# STM32H7RSxx register map
File version: 0.1
CPU: CM7 r0p1, little endian, MPU, FPU, 4 interrupt priority bits
Registers are 32-bit, read-write, reset 0x0 unless marked. A register's access mark holds for its fields unless they carry their own. Offsets are from the block's base; [hi:lo] are bit positions; {n}, {i} and the like mark numbered series.

## FLASH — Embedded Flash memory
Base 0x52002000
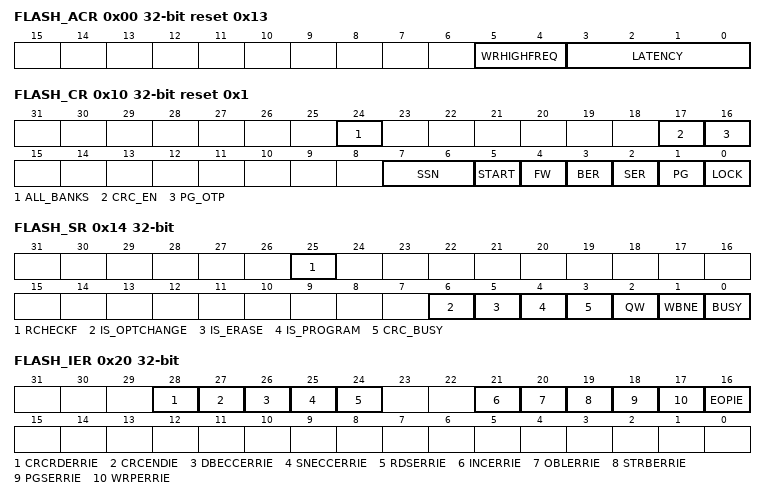
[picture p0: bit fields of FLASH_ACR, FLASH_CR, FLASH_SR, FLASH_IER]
0x00 FLASH_ACR reset 0x13 — Access control register
  [5:4] WRHIGHFREQ — Flash signal delay These bits are used to control the delay between non-volatile memory signals during programming operations. Application software has to program them to the correct value depending on the embedded Flash memory interface frequency. Please refer to Table 27 for details. Note: Embedded Flash does not verify that the configuration is correct.
  [3:0] LATENCY — Read latency These bits are used to control the number of wait states used during read operations on both non-volatile memory banks. The application software has to program them to the correct value depending on the embedded Flash memory interface frequency and voltage conditions. Please refer to Table 27 for details. ... Note: Embedded Flash does not verify that the configuration is correct.
    0=zero wait state used to read a word from non-volatile memory; 1=one wait state used to read a word from non-volatile memory; 2=two wait states used to read a word from non-volatile memory; 7=six wait states used to read a word from non-volatile memory; 15=fifteen wait states used to read from non-volatile memory
0x04 FLASH_KEYR wo — FLASH control key register
  [31:0] CUKEY — Control unlock key Following values must be written to FLASH_KEYR consecutively to unlock FLASH_CR register: 1st key = 0x4567 0123 2nd key = 0xCDEF 89AB Reads to this register returns zero. If above sequence is wrong or performed twice, the FLASH_CR register is locked until the next system reset, and access to it generates a bus error.
0x10 FLASH_CR reset 0x1 — FLASH control register
  [24] ALL_BANKS — All banks select bit When this bit is set the erase is done on all Flash Memory sectors. ALL_BANKS is used only if a bank erase is required (BER=1). In all others operations, this control bit is ignored.
  [17] CRC_EN — CRC enable Setting this bit enables the CRC calculation. CRC_EN does not start CRC calculation but enables CRC configuration through FLASH_CRCCR register. When CRC calculation is performed it can be disabled by clearing CRC_EN bit. Doing so sets CRCDATA to 0x0, clears CRC configuration and resets the content of FLASH_CRCDATAR register.
  [16] PG_OTP — Program Enable for OTP Area Set this bit to enable write operations to OTP area.
  [7:6] SSN — Sector erase selection number These bits are used to select the target sector for an erase operation (they are unused otherwise). ...
    0=Sector 0; 1=Sector 1; 7=Sector 7
  [5] START — Erase start control bit This bit is used to start a sector erase or a bank erase operation. The embedded Flash memory resets START when the corresponding operation has been acknowledged. The user application cannot access any embedded Flash memory register until the operation is acknowledged.
  [4] FW — Force write This bit forces a write operation even if the write buffer is not full. In this case all bits not written are set by hardware. The embedded Flash memory resets FW when the corresponding operation has been acknowledged. Note: Using a force-write operation prevents the application from updating later the missing bits with something else than 1, because it is likely that it will lead to permanent ECC error. Write forcing is effective only if the write buffer is not empty (in particular, FW does not start several write operations when the force-write operations are performed consecutively).
  [3] BER — Bank erase request Setting this bit requests a bank erase operation (user Flash memory only). Write protection error is triggered when a bank erase is required and some sectors are protected. BER has a higher priority than SER: if both are set, the embedded Flash memory executes a bank erase.
    0=Bank erase is not requested; 1=Bank erase is requested. Actual erase is started setting START bit in this register.
  [2] SER — Sector erase request Setting this bit requests a sector erase. Write protection error is triggered when a sector erase is required on at least one protected sector. BER has a higher priority than SER: if both bits are set, the embedded Flash memory executes a bank erase.
    0=Sector erase not requested; 1=Sector erase requested
  [1] PG — Internal buffer control bit Setting this bit enables internal buffer for write operations. This allows preparing program operations even if a sector or bank erase is ongoing. When PG is cleared, the internal buffer is disabled for write operations, and all the data stored in the buffer but not sent to the operation queue are lost.
    0=Internal buffer disabled for write operations; 1=Internal buffer enabled for write operations
  [0] LOCK — Configuration lock bit When this bit is set write to all other bits in this register, and to FLASH_IER register, are ignored. Clearing this bit requires the correct write sequence to FLASH_KEYR register (see this register for details). If a wrong sequence is executed, or if the unlock sequence is performed twice, this bit remains locked until the next system reset. During the write access to set LOCK bit from 0 to 1, it is possible to change the other bits of this register.
    0=FLASH_CR and FLASH_IER registers are unlocked; 1=Writes to FLASH_IER, and to other bits than LOCK in FLASH_CR, are ignored
0x14 FLASH_SR ro — FLASH status register
  [25] RCHECKF — Root code check flag This bit returns the status of the root code check performed following the first access to the Flash. This bit is cleared with RCHECKF bit in FLASH_FCR (optional).
    0=Root code check is fail. Reads to Flash returns zero, writes are ignored.; 1=Root code check is pass
  [6] IS_OPTCHANGE — Is an option change This bit is set together with BUSY when an option change operation is ongoing. It is cleared when BUSY is cleared. This flag can also raise with IS_PROGRAM or IS_ERASE, because a program or erase step is ongoing during option change.
  [5] IS_ERASE — Is an erase This bit is set together with BUSY when an erase operation is ongoing. It is cleared when BUSY is cleared. This flag can also raise with IS_OPTCHANGE, because an erase operation can happen during an option change.
  [4] IS_PROGRAM — Is a program This bit is set together with BUSY when a program operation is ongoing. It is cleared when BUSY is cleared. This flag can also raise with IS_OPTCHANGE, because an program operation can happen during an option change.
  [3] CRC_BUSY — CRC busy flag This bit is set when a CRC calculation is ongoing. This bit cannot be forced to 0. The user must wait until the CRC calculation has completed or disable CRC computation using CRC_EN bit in FLASH_CR register.
    0=No CRC calculation ongoing; 1=CRC calculation ongoing
  [2] QW — Wait queue flag This bit is set when a write, erase or option byte change operation is pending in the command queue buffer. It is not possible to know what type of programming operation is present in the queue. This flag is reset by hardware when all write, erase or option byte change operations have been executed and thus removed from the waiting queue(s). This bit cannot be forced to 0. It is reset after a deterministic time if no other operations are requested.
    0=No write, erase or option byte change operations waiting in the operation queues; 1=At least one write, erase or option byte change operation is waiting in the operation queue
  [1] WBNE — Write buffer not empty flag This bit is set when the embedded Flash memory is waiting for new data to complete the write buffer. In this state, the write buffer is not empty. WBNE is reset by hardware each time the write buffer is complete or the write buffer is emptied following one of the event below: the application software forces the write operation using FW bit in FLASH_CR the embedded Flash memory detects an error that involves data loss the application software has disabled write operations This bit cannot be forced to 0. To reset it, clear the write buffer by performing any of the above listed actions, or send the missing data.
    0=Write buffer empty or full; 1=Write buffer waiting data to complete
  [0] BUSY — Busy flag This bit is set when an effective write, erase or option byte change operation is ongoing. It is possible to know what type of operation is being executed reading the flags IS_PROGRAM, IS_ERASE and IS_OPTCHANGE. BUSY cannot be cleared by application. It is automatically reset by hardware every time a step in a write, erase or option byte change operation completes. It is not recommended to do software polling on BUSY to know when one operation completed because, depending of operation, more pulses are possible for one only operation. For software polling it is therefore better to use QW flag or to check the EOPF flag.
    0=No programming, erase or option byte change operation are being executed; 1=Programming, erase or option byte change operation are being executed. See flags IS_PROGRAM, IS_ERASE and IS_OPTCHANGE for details.
0x18 FLASH_FCR wo — FLASH status register
  [25] RCHECKF — Root code check flag clear Set this bit to clear RCHECKF bit in FLASH_SR.
0x20 FLASH_IER — FLASH interrupt enable register
  [28] CRCRDERRIE — CRC read error interrupt enable bit
    0=No interrupt is generated when CRCRDERRF bit is set in FLASH_ISR register; 1=An interrupt is generated when CRCRDERRF bit is set in FLASH_ISR register
  [27] CRCENDIE — CRC end of calculation interrupt enable bit
    0=No interrupt is generated when CRCEN bit is set in FLASH_ISR register; 1=An interrupt is generated when CRCEN bit is set in FLASH_ISR register
  [26] DBECCERRIE — ECC double detection error interrupt enable bit
    0=No interrupt is generated when DBECCERRF bit is set in FLASH_ISR register; 1=An interrupt is generated when DBECCERRF bit is set in FLASH_ISR register
  [25] SNECCERRIE — ECC single correction error interrupt enable bit
    0=No interrupt is generated when SNECCERRF bit is set in FLASH_ISR register; 1=An interrupt is generated when SNECCERRF bit is set in FLASH_ISR register
  [24] RDSERRIE — Read security error interrupt enable bit
    0=No interrupt is generated when RDSERRF bit is set in FLASH_ISR register; 1=An interrupt is generated when RDSERRF bit is set in FLASH_ISR register
  [21] INCERRIE — Inconsistency error interrupt enable bit
    0=No interrupt is generated when INCERRF bit is set in FLASH_ISR register; 1=An interrupt is generated when INCERRF bit is set in FLASH_ISR register
  [20] OBLERRIE — Option byte loading error interrupt enable bit
    0=No interrupt is generated when OBLERRF bit is set in FLASH_ISR register; 1=An interrupt is generated when OBLERRF bit is set in FLASH_ISR register
  [19] STRBERRIE — Strobe error interrupt enable bit
    0=No interrupt is generated when STRBERRF bit is set in FLASH_ISR register; 1=An interrupt is generated when STRBERRF bit is set in FLASH_ISR register
  [18] PGSERRIE — Programming sequence error interrupt enable bit
    0=No interrupt is generated when PGSERRF bit is set in FLASH_ISR register; 1=An interrupt is generated when PGSERRF bit is set in FLASH_ISR register
  [17] WRPERRIE — Write protection error interrupt enable bit
    0=No interrupt is generated when WRPERRF bit is set in FLASH_ISR register; 1=An interrupt is generated when WRPERRF bit is set in FLASH_ISR register
  [16] EOPIE — End-of-program interrupt control bit
    0=No interrupt is generated when OEPF bit is set in FLASH_ISR register; 1=An interrupt is generated when OEPF bit is set in FLASH_ISR register
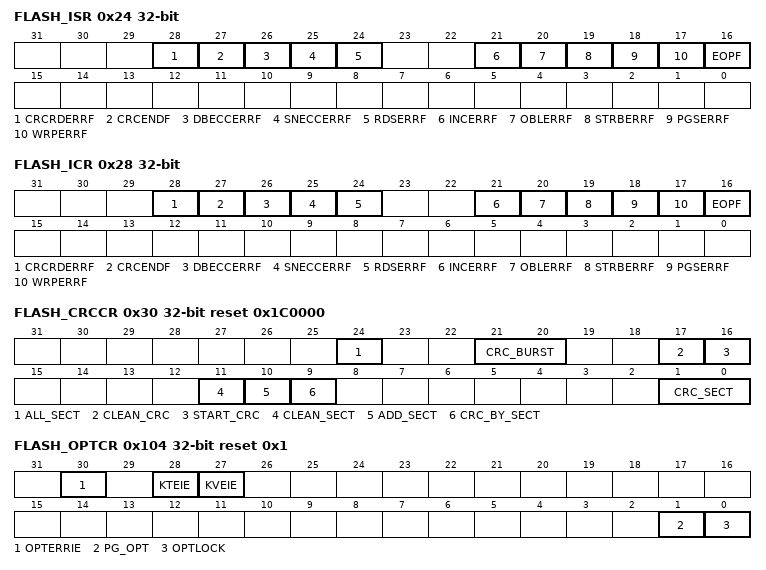
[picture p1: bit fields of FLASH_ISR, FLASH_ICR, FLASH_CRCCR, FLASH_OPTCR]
0x24 FLASH_ISR ro — FLASH interrupt status register
  [28] CRCRDERRF — CRC read error flag This bit is set when a word is found read protected during a CRC operation. An interrupt is generated if CRCRDIE is set. Setting CRCRDERRF bit in FLASH_ICR register clears this bit. This flag is valid only when CRCEND bit is set.
    0=No protected area detected inside addresses read by CRC; 1=At least one protected area has been detected inside address read by CRC. As a result CRC result is very likely incorrect.
  [27] CRCENDF — CRC end flag This bit is set when the CRC computation has completed. An interrupt is generated if CRCENDIE is set. It is not necessary to reset CRCEND before restarting CRC computation. Setting CRCENDF bit in FLASH_ICR register clears this bit.
    0=CRC computation not complete; 1=CRC computation complete
  [26] DBECCERRF — ECC double error flag This bit is set when an ECC double detection error occurs during a read operation. An interrupt is generated if DBECCERRIE is set. Setting DBECCERRF bit in FLASH_ICR register clears this bit.
    0=No ECC double detection error occurred; 1=ECC double detection error occurred
  [25] SNECCERRF — ECC single error flag This bit is set when an ECC single correction error occurs during a read operation. An interrupt is generated if SNECCERRIE is set. Setting SNECCERRF bit in FLASH_ICR register clears this bit.
    0=No ECC single correction error occurred; 1=ECC single correction error occurred
  [24] RDSERRF — Read security error flag This bit is set when a read security error occurs (read access to hide protected area with incorrect hide protection level). An interrupt is generated if RDSERRIE is set. Setting RDSERRF bit in FLASH_ICR register clears this bit.
    0=No security error occurred; 1=A security error occurred
  [21] INCERRF — Inconsistency error flag This bit is set when a inconsistency error occurs. An interrupt is generated if INCERRIE is set. Setting INCERRF bit in the FLASH_ICR register clears this bit.
    0=No inconsistency error occurred; 1=A inconsistency error occurred
  [20] OBLERRF — Option byte loading error flag This bit is set when an error is found during the option byte loading sequence. An interrupt is generated if OBLERRIE is set. Setting OBLERRF bit in the FLASH_ICR register clears this bit.
    0=No error found during option byte loading sequence; 1=Some errors found during option byte loading sequence
  [19] STRBERRF — Strobe error flag This bit is set when a strobe error occurs (when the master attempts to write several times the same byte in the write buffer). An interrupt is generated if the STRBERRIE bit is set. Setting STRBERRF bit in FLASH_ICR register clears this bit.
    0=No strobe error occurred; 1=Astrobe error occurred
  [18] PGSERRF — Programming sequence error flag This bit is set when a sequence error occurs. An interrupt is generated if the PGSERRIE bit is set. Setting PGSERRF bit in FLASH_ICR register clears this bit.
    0=No sequence error occurred; 1=Asequence error occurred
  [17] WRPERRF — Write protection error flag This bit is set when a protection error occurs during a program operation. An interrupt is also generated if the WRPERRIE is set. Setting WRPERRF bit in FLASH_ICR register clears this bit.
    0=No write protection error occurred; 1=A write protection error occurred
  [16] EOPF — End-of-program flag This bit is set when a programming operation completes. An interrupt is generated if the EOPIE is set. It is not necessary to reset EOPF before starting a new operation. Setting EOPF bit in FLASH_ICR register clears this bit.
    0=No programming operation completed; 1=A programming operation completed
0x28 FLASH_ICR wo — FLASH interrupt clear register
  [28] CRCRDERRF — CRC error flag clear Setting this bit clears CRCRDERRF flag in FLASH_ISR register.
  [27] CRCENDF — CRC end flag clear Setting this bit clears CRCENDF flag in FLASH_ISR register.
  [26] DBECCERRF — ECC double error flag clear Setting this bit clears DBECCERRF flag in FLASH_ISR register. If the SNECCERRF flag of FLASH_ISR register is also cleared, FLASH_ECCFAR register is reset to zero as well.
  [25] SNECCERRF — ECC single error flag clear Setting this bit clears SNECCERRF flag in FLASH_ISR register. If the DBECCERRF flag of FLASH_ISR register is also cleared, FLASH_ECCFAR register is reset to zero as well.
  [24] RDSERRF — Read security error flag clear Setting this bit clears RDSERRF flag in FLASH_ISR register.
  [21] INCERRF — Inconsistency error flag clear Setting this bit clears INCERRF flag in FLASH_ISR register.
  [20] OBLERRF — Option byte loading error flag clear Setting this bit clears OBLERRF flag in FLASH_ISR register.
  [19] STRBERRF — Strobe error flag clear Setting this bit clears STRBERRF flag in FLASH_ISR register.
  [18] PGSERRF — Programming sequence error flag clear Setting this bit clears PGSERRF flag in FLASH_ISR register.
  [17] WRPERRF — Write protection error flag clear Setting this bit clears WRPERRF flag in FLASH_ISR register.
  [16] EOPF — End-of-program flag clear Setting this bit clears EOPF flag in FLASH_ISR register.
0x30 FLASH_CRCCR access per field reset 0x1C0000 — FLASH CRC control register
  [24] ALL_SECT rw — All sectors selection When this bit is set all the sectors in user Flash are added to list of sectors on which the CRC shall be calculated. This bit is cleared when CRC computation starts.
  [21:20] CRC_BURST rw — CRC burst size CRC_BURST bits set the size of the bursts that are generated by the CRC calculation unit. A Flash word is 128-bit.
    0=every burst has a size of 4 Flash words (64 Bytes); 1=every burst has a size of 16 Flash words (256 Bytes); 2=every burst has a size of 64 Flash words (1 Kbytes); 3=every burst has a size of 256 Flash words (4 Kbytes)
  [17] CLEAN_CRC wo — CRC clear bit Setting CLEAN_CRC to 1 clears the current CRC result stored in the FLASH_CRCDATAR register.
  [16] START_CRC rw — CRC start bit START_CRC bit triggers a CRC calculation using the current configuration. No CRC calculation can launched when an option byte change operation is ongoing because all read accesses to embedded Flash memory registers are put on hold until the option byte change operation has completed. This bit is cleared when CRC computation starts.
  [11] CLEAN_SECT wo — CRC sector list clear bit When this bit is set the list of sectors on which the CRC is calculated is cleared.
  [10] ADD_SECT wo — CRC sector select bit When this bit is set the sector whose number is written in CRC_SECT is added to the list of sectors on which the CRC is calculated.
  [9] CRC_BY_SECT rw — CRC sector mode select bit When this bit is set the CRC calculation is performed at sector level, on the sectors present in the list of sectors. To add a sector to this list, use ADD_SECT and CRC_SECT bits. To clean the list, use CLEAN_SECT bit. When CRC_BY_SECT is cleared the CRC calculation is performed on all addresses defined between start and end addresses defined in FLASH_CRCSADDR and FLASH_CRCEADDR registers.
  [1:0] CRC_SECT rw — CRC sector number CRC_SECT is used to select one user Flash sectors to be added to the list of sectors on which the CRC is calculated. The CRC can be computed either between two addresses (using registers FLASH_CRCSADDR and FLASH_CRCEADDR) or on a list of sectors using this register. If this latter option is selected, it is possible to add a sector to the list of sectors by programming the sector number in CRC_SECT and then setting ADD_SECT bit. The list of sectors can be erased either by setting CLEAN_SECT bit or by disabling the CRC computation. ...
    0=sector 0 for CRC; 1=sector 1 for CRC; 7=sector 7 for CRC
0x34 FLASH_CRCSADDR — FLASH CRC start address register
  [16:6] CRC_START_ADDR — CRC start address This register is used when CRC_BY_SECT is cleared. It must be programmed to the address of the first Flash word to use for the CRC calculation, done burst by burst. CRC computation starts at an address aligned to the burst size defined in CRC_BURST of FLASH_CRCCR register. Hence least significant bits [5:0] of the address are set by hardware to 0 (minimum burst size= 64 bytes). The address is relative to the Flash bank.
0x38 FLASH_CRCEADDR — FLASH CRC end address register
  [16:6] CRC_END_ADDR — CRC end address This register is used when CRC_BY_SECT is cleared. It must be programmed to the address of the Flash word starting the last burst of the CRC calculation. The burst size is defined in CRC_BURST of FLASH_CRCCR register. The least significant bits [5:0] of the address are set by hardware to 0 (minimum burst size= 64 bytes). The address is relative to the Flash bank.
0x3C FLASH_CRCDATAR ro — FLASH CRC data register
  [31:0] CRC_DATA — CRC result This bitfield contains the result of the last CRC calculation. The value is valid only when CRC calculation completed (CRCENDF is set in FLASH_ISR register). CRC_DATA is cleared when CRC_EN is cleared in FLASH_CR register (CRC disabled), or when CLEAN_CRC bit is set in FLASH_CRCCR register.
0x40 FLASH_ECCSFADDR ro — FLASH ECC single error fail address
  [31:0] SEC_FADD — ECC single error correction fail address When a single ECC error correction occurs during a read operation, the SEC_FADD bitfield contains the system bus address that generated the error. This register is automatically cleared when SNECCERRF flag that generated the error is cleared. Note that only the first address that generated an ECC single error correction error is saved in this register.
0x44 FLASH_ECCDFADDR ro — FLASH ECC double error fail address
  [31:0] DED_FADD — ECC double error detection fail address When a double ECC detection occurs during a read operation, the DED_FADD bitfield contains the system bus address that generated the error. This register is automatically cleared when the DBECCERRF flag that generated the error is cleared. Note that only the first address that generated an ECC double error detection error is saved in this register.
0x100 FLASH_OPTKEYR wo — FLASH options key register
  [31:0] OCUKEY — Options configuration unlock key Following values must be written to FLASH_OPTKEYR consecutively to unlock FLASH_OPTCR register: 1st key = 0x0819 2A3B 2nd key = 0x4C5D 6E7F Reads to this register returns zero. If above sequence is performed twice locks up the corresponding register/bit until the next system reset, and generates a bus error.
0x104 FLASH_OPTCR reset 0x1 (reset mask 0xFFFFFFF) — FLASH options control register
  [30] OPTERRIE — Option byte change error interrupt enable bit This bit controls if an interrupt has to be generated when an error occurs during an option byte change.
    0=no interrupt is generated when an error occurs during an option byte change; 1=an interrupt is generated when and error occurs during an option byte change
  [28] KTEIE — Key transfer error interrupt enable bit This bit controls if an interrupt has to be generated when KTEF is set in FLASH_OPTISR.
    0=no interrupt is generated when a key transfer error occurs; 1=an interrupt is generated when a key transfer error occurs
  [27] KVEIE — Key valid error interrupt enable bit This bit controls if an interrupt has to be generated when KVEF is set in FLASH_OPTISR.
    0=no interrupt is generated when a key valid error occurs; 1=an interrupt is generated when a key valid error occurs
  [1] PG_OPT — Program options
    0=Update operations to user option bytes and option byte keys do not start; 1=Write operation to user option bytes and option byte keys is enabled
  [0] OPTLOCK — Options lock When this bit is set write to all other bits in this register, and write to OTP words, option bytes and option bytes keys control registers, are ignored. Clearing this bit requires the correct write sequence to FLASH_OPTKEYR register (see this register for details). If a wrong sequence is executed, or the unlock sequence is performed twice, this bit remains locked until next system reset. During the write access to set LOCK bit from 0 to 1, it is possible to change the other bits of this register.
    0=OTP words, FLASH_OPTCR, FLASH_OBKCR and FLASH_xxSRP registers are unlocked; 1=Writes to OTP words, FLASH_OBKCR, FLASH_xxSRP and to other bits than OPTLOCK in FLASH_OPTCR, are ignored
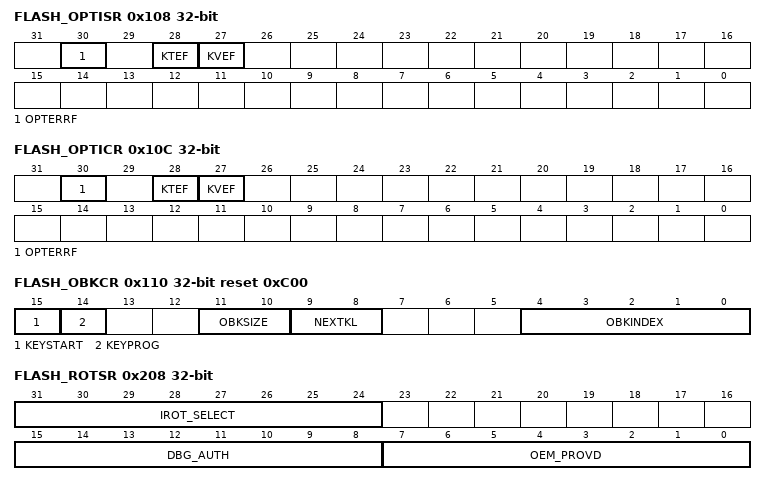
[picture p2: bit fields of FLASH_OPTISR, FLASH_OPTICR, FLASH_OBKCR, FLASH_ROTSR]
0x108 FLASH_OPTISR ro reset not defined — FLASH options interrupt status register
  [30] OPTERRF — Option byte change error flag When OPTERRF is set, the option byte change operation did not successfully complete. An interrupt is generated when this flag is raised if the OPTERRIE bit of FLASH_OPTCR register is set. Setting OPTERRF of register FLASH_OPTICR clears this bit.
    0=No option byte change errors occurred; 1=One or more errors occurred during an option byte change operation
  [28] KTEF — Key transfer error flag This bit is set when embedded Flash signals an error to the SAES peripheral. It happens when the key size (128-bit or 256-bit) is not matching between embedded Flash OBKSIZE[1:0] and KEYSIZE bit in SAES_CR register. It also happen when an ECC dual error detection occurred while embedded Flash loaded an option byte key for the SAES peripheral. When KTEF is set write to START bit in FLASH_OBKCR is ignored. An interrupt is generated when this flag is raised if the KTEIE bit of FLASH_OPTCR register is set. Setting KTEF bit of register FLASH_OPTICR clears this bit.
  [27] KVEF — Key valid error flag This bit is set when loading an unknown or corrupted option byte key. More specifically: Embedded Flash did not find an option byte key that corresponds to the given OBKINDEX[4:0] and the requested HDPL (optionally modified by NEXTKL[1:0]). It can happen for example when requested key has not being provisioned. A double error detection was found when loading the requested option byte key. In this case, if this key is provisioned again the error should disappear. When KVEF is set write to START bit in FLASH_OBKCR is ignored. An interrupt is generated when this flag is raised if the KVEIE bit of FLASH_OPTCR register is set. Setting KVEF bit of register FLASH_OPTICR clears this bit.
0x10C FLASH_OPTICR wo reset not defined — FLASH options interrupt clear register
  [30] OPTERRF — Option byte change error flag Set this bit to clear OPTERRF flag in FLASH_OPTISR register.
  [28] KTEF — key transfer error flag Set this bit to clear KTEF flag in FLASH_OPTISR register.
  [27] KVEF — key valid error flag Set this bit to clear KVEF flag in FLASH_OPTISR register.
0x110 FLASH_OBKCR reset 0xC00 — FLASH option byte key control register
  [15] KEYSTART — Key option start This bit is used to start the option byte key operation defined by the PROG bit. The embedded Flash memory resets START when the corresponding operation has been acknowledged.
  [14] KEYPROG — Key program This bit must be set to write option byte keys (keys are read otherwise).
    0=Read key. Result of the operation is stored in FLASH_OBKDRx registers, if applicable.; 1=Program key if PG_OPT is set in FLASH_OPTCR register, and KDREF flag is cleared in FLASH_OPTISR register. Correct key information must be stored in FLASH_OBKDRx register before setting PROG and START bits.
  [11:10] OBKSIZE — Option byte key size Application must use this bitfield to specify how many bits must be used for the new key. Embedded Flash ignores OBKSIZE during read of option keys because size is stored with the key.
    0=Key size is 32 bits; 1=Key size is 64 bits; 2=Key size is 128 bits; 3=Key size is 256 bits
  [9:8] NEXTKL — Next key level 10 or 11: reserved
    0=OBKINDEX represents the index of the option byte key stored for the hide protection level indicated in SBS_HDPLSR; 1=OBKINDEX represents the index of the option byte key stored for the hide protection level indicated in SBS_HDPLSR plus one (e.g. if HDPL=1 in SBS_HDPLR the key of level 2 is selected).
  [4:0] OBKINDEX — Option byte key index This bitfield represents the index of the option byte key in a given hide protection level. Reading keys with index lower that 8, the value is not be available in OBKDRx registers. It is instead sent directly to SAES peripheral. All others keys can be read using OBKDRx registers. Up to 32 keys can be provisioned per hide protection level (0, 1 or 2), provided there is enough space left in the Flash to store them.
{0x118+4i} FLASH_OBKDR{i} (i=0..7) — FLASH option bytes key data register {i}
  [31:0] OBKDATA — option byte key data, bits [31+x:0+x] Data register used in conjunction with FLASH_OBKCR register. Reading this register (read value once), or incrementing HDPL value in SBS peripheral automatically clears OBKDATA to 0x0. Writing this register prevents reading OBKDATA until option byte key programming sequence is completed.
0x200 FLASH_NVSR ro (reset mask 0xFFFF0000) — FLASH non-volatile status register
  [7:0] NVSTATE — Non-volatile state others: invalid configuration.
    180=OPEN device; 81=CLOSED device
0x204 FLASH_NVSRP (reset mask 0xFFFF0000) — FLASH security status register programming
  [7:0] NVSTATE — Non-volatile state programming Write to change corresponding bits in FLASH_NVSR register: Actual option byte change from close to open is triggered only after memory clear hardware process is confirmed. When NVSTATE=0xB4 (resp. 0x51) writing any other value than 0x51 (resp. 0xB4) triggers an option byte change error (OPTERRF).
    180=OPEN; 81=CLOSE
0x208 FLASH_ROTSR ro (reset mask 0xFFFF0000) — FLASH RoT status register
  [31:24] IROT_SELECT — iRoT selection This option is ignored for STM32H7R devices (OEM iRoT is always selected). Any other value: OEM iRoT is selected at boot.
    180=ST iRoT is selected at boot
  [15:8] DBG_AUTH — Debug authentication method Any other value: no authentication method selected (NotSet).
    180=Locked device (no debug allowed); 81=Authentication method using ECDSA signature (NIST P256); 138=Authentication method using password; 111=Delegated debug (to OEM iRoT code in user Flash)
  [7:0] OEM_PROVD — OEM provisioned device Any other value: device is not provisioned by the OEM.
    180=Device has been provisioned by the OEM
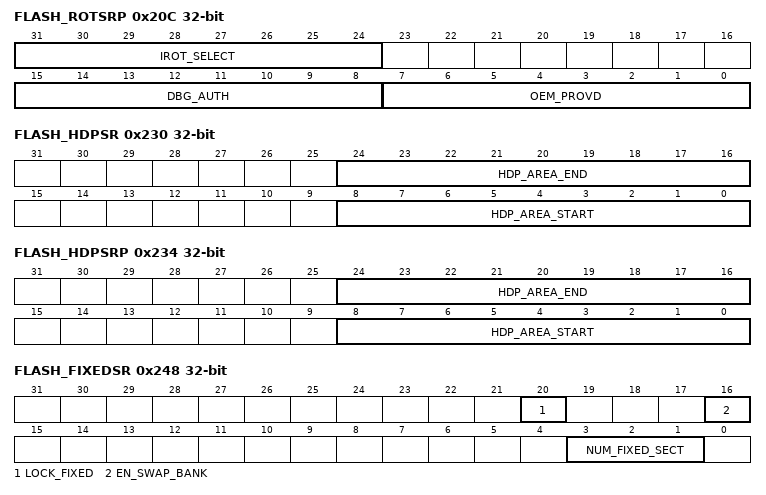
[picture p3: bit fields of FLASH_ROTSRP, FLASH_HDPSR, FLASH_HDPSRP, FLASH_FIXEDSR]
0x20C FLASH_ROTSRP access per field (reset mask 0xFFFF0000) — FLASH RoT status register programming
  [31:24] IROT_SELECT ro — iRoT selection This option is ignored for STM32H7R devices. Write to change corresponding bits in FLASH_ROTSR register. Write are ignored if HDPL is greater than 1 and if NVSTATE is not 0xB4 (OPEN).
  [15:8] DBG_AUTH rw — Debug authentication method programming Write to change corresponding bits in FLASH_ROTSR register. Write are ignored if HDPL is greater than 0.
  [7:0] OEM_PROVD rw — OEM provisioned device Write to change corresponding bits in FLASH_ROTSR register. Write are ignored if HDPL is greater than 1.
0x210 FLASH_OTPLSR ro (reset mask 0xFFFF0000) — FLASH OTP lock status register
  [15:0] OTPL — OTP lock n Block n corresponds to OTP 16-bit word 32 x n to 32 x n + 31. OTPL[n] = 1 indicates that all OTP 16-bit words in OTP Block n are locked and can no longer be programmed. OTPL[n] = 0 indicates that all OTP 16-bit words in OTP Block n are not locked and can still be modified.
0x214 FLASH_OTPLSRP (reset mask 0xFFFF0000) — FLASH OTP lock status register programming
  [15:0] OTPL — OTP lock n programming Write to change corresponding option byte bit in FLASH_OTPLSR. OTPL bits can be only be set, not cleared.
0x218 FLASH_WRPSR (reset mask 0xFFFF0000) — FLASH write protection status register
  [7:0] WRPS — Write protection for sector n This bit reflects the write protection status of user Flash sector n
    0=sector n is write protected; 1=sector n is not write protected
0x21C FLASH_WRPSRP (reset mask 0xFFFF0000) — FLASH write protection status register programming
  [7:0] WRPS — Write protection for sector n programming Write to change corresponding bit in FLASH_WRPSR
0x230 FLASH_HDPSR ro (reset mask 0xF000FFFF) — FLASH hide protection status register
  [24:16] HDP_AREA_END — Hide protection user Flash area end This option sets the end address that contains the last 256-byte block of the hide protection (HDP) area in user Flash area. If HDP_AREA_END=HDP_AREA_START all the sectors are protected. If HDP_AREA_END<HDP_AREA_START no sectors are protected.
  [8:0] HDP_AREA_START — Hide protection user Flash area start This option sets the start address that contains the first 256-byte block of the hide protection (HDP) area in user Flash area. If HDP_AREA_END=HDP_AREA_START all the sectors are protected. If HDP_AREA_END<HDP_AREA_START no sectors are protected.
0x234 FLASH_HDPSRP (reset mask 0xF000FFFF) — FLASH hide protection status register programming
  [24:16] HDP_AREA_END — Hide protection user Flash area end programming Write to change corresponding option byte bits in FLASH_HDPSR. If HDP_AREA_END=HDP_AREA_START all the sectors are protected. If HDP_AREA_END<HDP_AREA_START no sectors are protected.
  [8:0] HDP_AREA_START — Hide protection user Flash area start programming Write to change corresponding option byte bits in FLASH_HDPSR. If HDP_AREA_END=HDP_AREA_START all the sectors are protected. If HDP_AREA_END<HDP_AREA_START no sectors are protected.
0x248 FLASH_FIXEDSR ro (reset mask 0xFFF0F000) — FLASH fixed bank status register
  [20] LOCK_FIXED — Lock fixed bank parameters When set writes to FLASH _FIXEDSRP are ignored.
  [16] EN_SWAP_BANK — Enable swap bank For the sectors not allocated to bank F using NUM_FIXED_SECT bits they are managed according to this bit value:
    0=All sectors not assigned to bank F are allocated to bank A. Accessing to bank B sectors return a bus error, and erase request to those sectors are ignored.; 1=All sectors not assigned to bank F are evenly allocated between bank A and bank B, based on SWAP_BANK option bit
  [3:1] NUM_FIXED_SECT — Number of fixed sectors The value set in this bitfield (adding one 0 as LSB) defines the even number of sectors that are not affected by the SWAP_BANK bit. For example, if NUM_FIXED_SECT=100 the number of fixed sectors is 0b1000, i.e. eight. This option is meaningful only when EN_SWAP_BANK option bit is set.
0x250 FLASH_EPOCHSR ro (reset mask 0xFFFF0000) — FLASH epoch status register
  [23:0] EPOCH — Epoch This value is distributed by hardware to the SAES peripheral.
0x254 FLASH_EPOCHSRP (reset mask 0xFFFF0000) — FLASH RoT status register programming
  [23:0] EPOCH — Epoch programming Write to change corresponding bits in FLASH_EPOCHSR register.
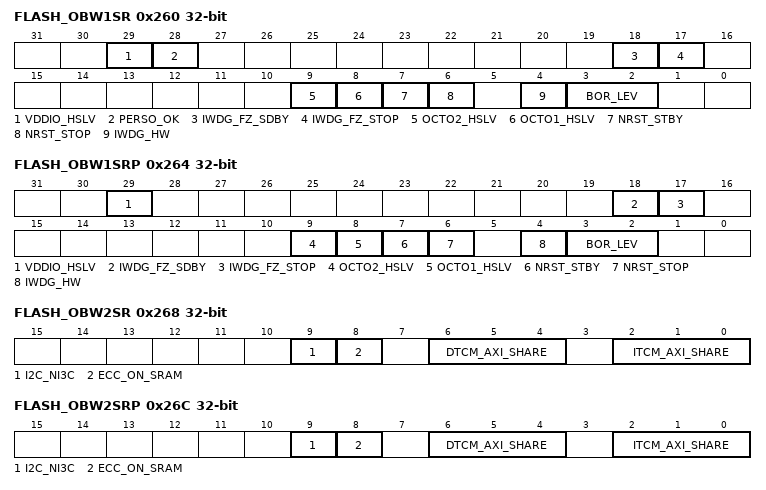
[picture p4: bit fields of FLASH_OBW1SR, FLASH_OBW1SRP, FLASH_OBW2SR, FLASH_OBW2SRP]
0x260 FLASH_OBW1SR ro reset not defined — FLASH option byte word 1 status register
  [29] VDDIO_HSLV — I/O High-Speed at Low-Voltage This bit indicates that the product operates below 2.5 V.
    0=Product working in the full voltage range, I/O speed optimization at low-voltage disabled; 1=Product operating below 2.5 V, I/O speed optimization at low-voltage feature allowed
  [28] PERSO_OK — Personalization OK This bit is set on STMicroelectronics production line.
  [18] IWDG_FZ_SDBY — IWDG standby mode freeze When set the independent watchdog IWDG is frozen in system Standby mode.
    0=Independent watchdog frozen in Standby mode; 1=Independent watchdog keep running in Standby mode
  [17] IWDG_FZ_STOP — IWDG stop mode freeze When set the independent watchdog IWDG is frozen in system Stop mode.
    0=Independent watchdog frozen in Stop mode; 1=Independent watchdog keep running in Stop mode
  [9] OCTO2_HSLV — XSPIM_P2 High-Speed at Low-Voltage
    0=I/O XSPIM_P2 High-Speed option disabled; 1=I/O XSPIM_P2 High-Speed option enabled
  [8] OCTO1_HSLV — XSPIM_P1 High-Speed at Low-Voltage
    0=I/O XSPIM_P1 High-Speed option disabled; 1=I/O XSPIM_P1 High-Speed option enabled
  [7] NRST_STBY — Reset on standby mode
    0=Independent WDG generates a reset if STANDBY mode is requested; 1=Independent WDG does not generate a reset if STANDBY mode is requested
  [6] NRST_STOP — Reset on stop mode
    0=Independent WDG generates a reset if STOP mode is requested; 1=Independent WDG does not generate a reset if STOP mode is requested
  [4] IWDG_HW — Independent watchdog HW Control
    1=IWDG watchdog is controlled by software; 0=IWDG watchdog is controller by hardware
  [3:2] BOR_LEV — Brownout level These bits reflects the power level that generates a system reset.
    0=BOR OFF, POR/PDR reset threshold level is applied; 1=BOR Level 1, the threshold level is low (around 2.1 V); 2=BOR Level 2, the threshold level is medium (around 2.4 V); 3=BOR Level 3, the threshold level is high (around 2.7 V)
0x264 FLASH_OBW1SRP reset not defined — FLASH option byte word 1 status register programming
  [29] VDDIO_HSLV — I/O High-Speed at Low-Voltage programming Write to change corresponding bit in FLASH_OBW1SR register.
  [18] IWDG_FZ_SDBY — IWDG standby mode freeze programming Write to change corresponding bit in FLASH_OBW1SR register.
  [17] IWDG_FZ_STOP — IWDG stop mode freeze Write to change corresponding bit in FLASH_OBW1SR register.
  [9] OCTO2_HSLV — XSPIM_P2 High-Speed at Low-Voltage programming Write to change corresponding bit in FLASH_OBW1SR register.
  [8] OCTO1_HSLV — XSPIM_P1 High-Speed at Low-Voltage Write to change corresponding bit in FLASH_OBW1SR register.
  [7] NRST_STBY — Reset on standby mode programming Write to change corresponding bit in FLASH_OBW1SR register.
  [6] NRST_STOP — Reset on stop mode programming Write to change corresponding bit in FLASH_OBW1SR register.
  [4] IWDG_HW — Independent watchdog HW Control Write to change corresponding bit in FLASH_OBW1SR register.
  [3:2] BOR_LEV — Brownout level Write to change corresponding bits in FLASH_OBW1SR register.
0x268 FLASH_OBW2SR ro reset not defined — FLASH option byte word 2 status register
  [9] I2C_NI3C — I2C Not I3C
    0=I3C is selected; 1=I2C is selected
  [8] ECC_ON_SRAM
  [6:4] DTCM_AXI_SHARE — DTCM SRAM configuration
  [2:0] ITCM_AXI_SHARE — ITCM SRAM configuration
0x26C FLASH_OBW2SRP reset not defined — FLASH option byte word 2 status register programming
  [9] I2C_NI3C — I2C Not I3C Write to change corresponding bit in FLASH_OBW2SR register.
  [8] ECC_ON_SRAM — ECC on SRAM programming Write to change corresponding bit in FLASH_OBW2SR register.
  [6:4] DTCM_AXI_SHARE — DTCM AXI share programming Write to change corresponding bits in the FLASH_OBW2SR register. Bit 2 should be kept to 0: DTCM_AXI_SHARE = “000” or “011”: DTCM 64 Kbytes DTCM_AXI_SHARE = “001”: DTCM 128 Kbytes DTCM_AXI_SHARE = “010”: DTCM 192 Kbytes
  [2:0] ITCM_AXI_SHARE — ITCM AXI share programming Write to change corresponding bits in FLASH_OBW2SR register. Bit 2 should be kept to 0: ITCM_AXI_SHARE: = “000” or “011”: ITCM 64 Kbytes ITCM_AXI_SHARE = “001”: ITCM 128 Kbytes ITCM_AXI_SHARE = “010”: ITCM 192 Kbytes
